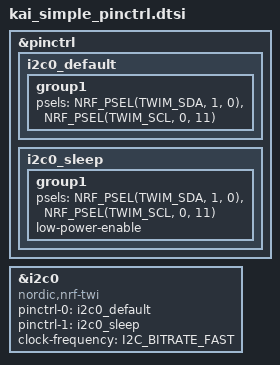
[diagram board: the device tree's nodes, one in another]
/*
 * Copyright (c) 2024 The ZMK Contributors
 *
 * SPDX-License-Identifier: MIT
 */

&pinctrl {
    /* I2C Configuration using dedicated I2C pins */
    i2c0_default: i2c0_default {
        group1 {
            /* SDA: P1.00 (D6), SCL: P0.11 (D7) */
            psels = <NRF_PSEL(TWIM_SDA, 1, 0)>,
                    <NRF_PSEL(TWIM_SCL, 0, 11)>;
        };
    };

    i2c0_sleep: i2c0_sleep {
        group1 {
            psels = <NRF_PSEL(TWIM_SDA, 1, 0)>,
                    <NRF_PSEL(TWIM_SCL, 0, 11)>;
            low-power-enable;
        };
    };
};

&i2c0 {
    compatible = "nordic,nrf-twi";
    status = "okay";
    pinctrl-0 = <&i2c0_default>;
    pinctrl-1 = <&i2c0_sleep>;
    pinctrl-names = "default", "sleep";
    clock-frequency = <I2C_BITRATE_FAST>; 
 };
